# N32G401 register map
Vendor: Nationstech Ltd.; File version: 1.0
Registers are 32-bit, read-write, reset 0x0 unless marked. A register's access mark holds for its fields unless they carry their own. Offsets are from the block's base; [hi:lo] are bit positions; {n}, {i} and the like mark numbered series.

## TIM1 — Advanced timer
Base 0x40012C00
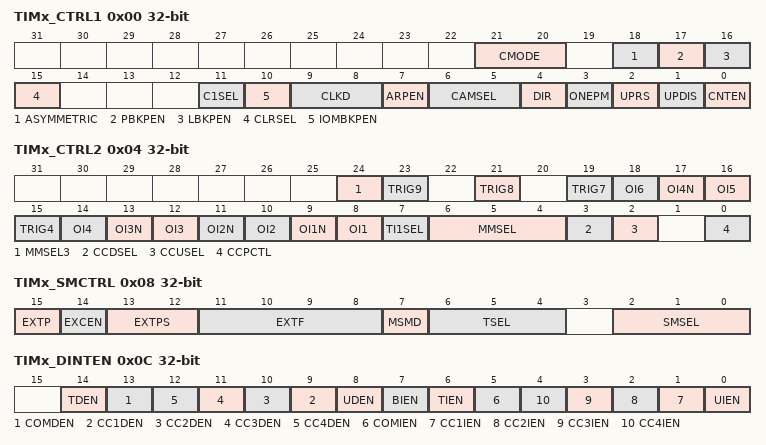
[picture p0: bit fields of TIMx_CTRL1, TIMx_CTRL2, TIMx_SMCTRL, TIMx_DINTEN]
0x00 TIMx_CTRL1 (reset mask 0x3FFFF)
  [21:20] CMODE, [18] ASYMMETRIC, [17] PBKPEN, [16] LBKPEN, [15] CLRSEL, [11] C1SEL, [10] IOMBKPEN, [9:8] CLKD, [7] ARPEN, [6:5] CAMSEL, [4] DIR, [3] ONEPM, [2] UPRS, [1] UPDIS, [0] CNTEN
0x04 TIMx_CTRL2 (reset mask 0x57FFD)
  [24] MMSEL3
  [23] TRIG9
  [21] TRIG8
  [19] TRIG7
  [2n+6] OI{n} (n=1..6)
  [17] OI4N — OI5
  [15] TRIG4
  [13] OI3N
  [11] OI2N
  [9] OI1N
  [7] TI1SEL
  [6:4] MMSEL
  [3] CCDSEL
  [2] CCUSEL
  [0] CCPCTL
0x08 TIMx_SMCTRL
  [15] EXTP, [14] EXCEN, [13:12] EXTPS, [11:8] EXTF, [7] MSMD, [6:4] TSEL, [2:0] SMSEL
0x0C TIMx_DINTEN
  [14] TDEN, [13] COMDEN, [n+8] CC{n}DEN (n=1..4), [8] UDEN, [7] BIEN, [6] TIEN, [5] COMIEN, [n] CC{n}IEN (n=1..4), [0] UIEN
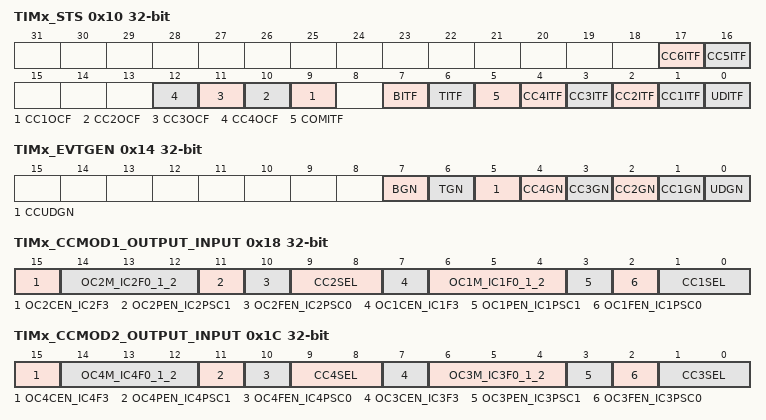
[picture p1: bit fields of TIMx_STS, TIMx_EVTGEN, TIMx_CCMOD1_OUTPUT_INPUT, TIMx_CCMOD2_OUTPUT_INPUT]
0x10 TIMx_STS
  [17] CC6ITF, [16] CC5ITF, [n+8] CC{n}OCF (n=1..4), [7] BITF, [6] TITF, [5] COMITF, [n] CC{n}ITF (n=1..4), [0] UDITF
0x14 TIMx_EVTGEN
  [7] BGN, [6] TGN, [5] CCUDGN, [n] CC{n}GN (n=1..4), [0] UDGN
0x18 TIMx_CCMOD1_OUTPUT_INPUT
  [15] OC2CEN_IC2F3, [14:12] OC2M_IC2F0_1_2, [11] OC2PEN_IC2PSC1, [10] OC2FEN_IC2PSC0, [9:8] CC2SEL, [7] OC1CEN_IC1F3, [6:4] OC1M_IC1F0_1_2, [3] OC1PEN_IC1PSC1, [2] OC1FEN_IC1PSC0, [1:0] CC1SEL
0x1C TIMx_CCMOD2_OUTPUT_INPUT
  [15] OC4CEN_IC4F3, [14:12] OC4M_IC4F0_1_2, [11] OC4PEN_IC4PSC1, [10] OC4FEN_IC4PSC0, [9:8] CC4SEL, [7] OC3CEN_IC3F3, [6:4] OC3M_IC3F0_1_2, [3] OC3PEN_IC3PSC1, [2] OC3FEN_IC3PSC0, [1:0] CC3SEL
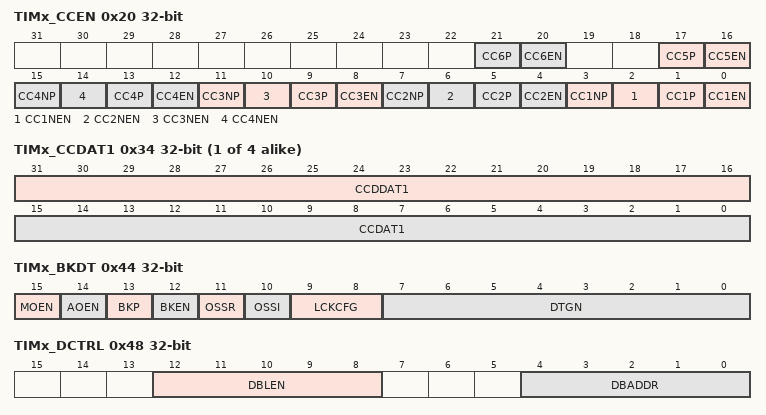
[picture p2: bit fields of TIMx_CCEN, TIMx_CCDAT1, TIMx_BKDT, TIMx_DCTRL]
0x20 TIMx_CCEN (reset mask 0x333FFF)
  [4n-3] CC{n}P (n=1..6), [4n-4] CC{n}EN (n=1..6), [4n-1] CC{n}NP (n=1..4), [4n-2] CC{n}NEN (n=1..4)
0x24 TIMx_CNT
  [15:0] CNT
0x28 TIMx_PSC
  [15:0] PSC
0x2C TIMx_AR
  [15:0] AR
0x30 TIMx_REPCNT
  [7:0] REPCNT
{0x30+4i} TIMx_CCDAT{i} (reset mask 0xFFFF) (i=1..4)
  [31:16] CCDDAT{i}, [15:0] CCDAT{i}
0x44 TIMx_BKDT
  [15] MOEN, [14] AOEN, [13] BKP, [12] BKEN, [11] OSSR, [10] OSSI, [9:8] LCKCFG, [7:0] DTGN
0x48 TIMx_DCTRL
  [12:8] DBLEN, [4:0] DBADDR
0x4C TIMx_DADDR
  [15:0] BURST
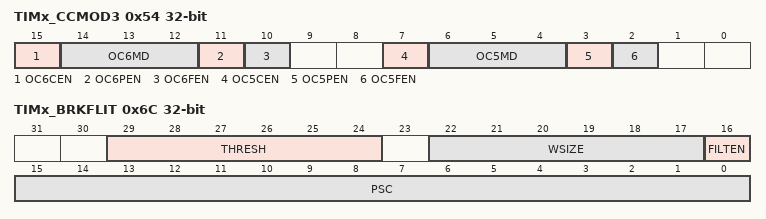
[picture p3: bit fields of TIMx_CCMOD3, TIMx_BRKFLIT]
0x54 TIMx_CCMOD3
  [15] OC6CEN, [14:12] OC6MD, [11] OC6PEN, [10] OC6FEN, [7] OC5CEN, [6:4] OC5MD, [3] OC5PEN, [2] OC5FEN
{0x44+4i} TIMx_CCDAT{i} (i=5..9)
  [15:0] CCDAT{i}
0x6C TIMx_BRKFLIT (reset mask 0xFFFF)
  [29:24] THRESH, [22:17] WSIZE, [16] FILTEN, [15:0] PSC

## TIM8 — Advanced timer
Base 0x40013400
Registers as TIM1, without TIMx_CCDAT{n} (n=7..9); these are added or differ:
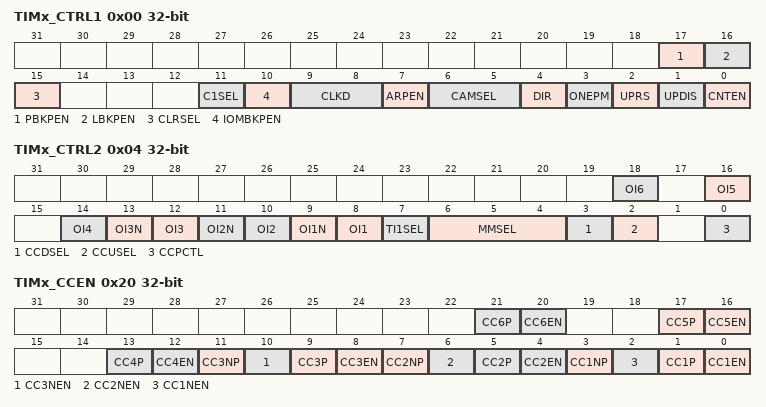
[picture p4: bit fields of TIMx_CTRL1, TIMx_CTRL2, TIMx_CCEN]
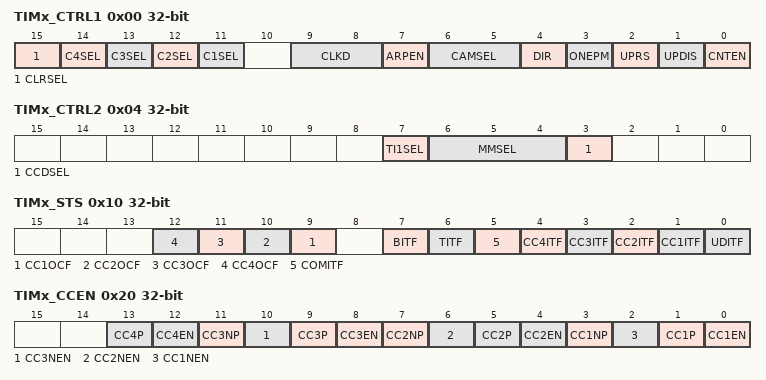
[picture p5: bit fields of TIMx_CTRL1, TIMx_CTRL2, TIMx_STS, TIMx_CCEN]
0x00 TIMx_CTRL1
  [17] PBKPEN, [16] LBKPEN, [15] CLRSEL, [11] C1SEL, [10] IOMBKPEN, [9:8] CLKD, [7] ARPEN, [6:5] CAMSEL, [4] DIR, [3] ONEPM, [2] UPRS, [1] UPDIS, [0] CNTEN
0x04 TIMx_CTRL2
  [2n+6] OI{n} (n=1..6), [13] OI3N, [11] OI2N, [9] OI1N, [7] TI1SEL, [6:4] MMSEL, [3] CCDSEL, [2] CCUSEL, [0] CCPCTL
0x20 TIMx_CCEN
  [4n-3] CC{n}P (n=1..6), [4n-4] CC{n}EN (n=1..6), [11] CC3NP, [10] CC3NEN, [7] CC2NP, [6] CC2NEN, [3] CC1NP, [2] CC1NEN
{0x30+4i} TIMx_CCDAT{i} (i=1..4)
  [15:0] CCDAT{i}

## TIM2 — General purpose timer
Base 0x40000000
Registers as TIM8, without TIMx_REPCNT, TIMx_BKDT, TIMx_CCMOD3, TIMx_CCDAT5, TIMx_CCDAT6, TIMx_BRKFLIT; these are added or differ:
0x00 TIMx_CTRL1
  [15] CLRSEL, [n+10] C{n}SEL (n=1..4), [9:8] CLKD, [7] ARPEN, [6:5] CAMSEL, [4] DIR, [3] ONEPM, [2] UPRS, [1] UPDIS, [0] CNTEN
0x04 TIMx_CTRL2
  [7] TI1SEL, [6:4] MMSEL, [3] CCDSEL
0x10 TIMx_STS
  [n+8] CC{n}OCF (n=1..4), [7] BITF, [6] TITF, [5] COMITF, [n] CC{n}ITF (n=1..4), [0] UDITF
0x20 TIMx_CCEN
  [4n-3] CC{n}P (n=1..4), [4n-4] CC{n}EN (n=1..4), [11] CC3NP, [10] CC3NEN, [7] CC2NP, [6] CC2NEN, [3] CC1NP, [2] CC1NEN
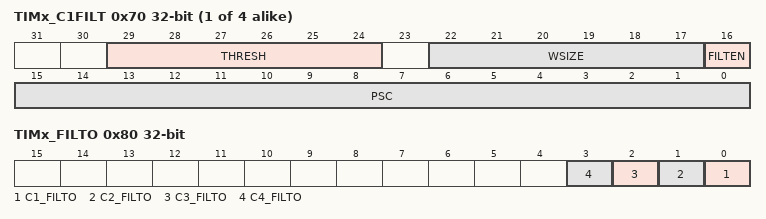
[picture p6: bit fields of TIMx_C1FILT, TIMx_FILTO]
{0x6C+4i} TIMx_C{i}FILT (reset mask 0xFFFF) (i=1..4)
  [29:24] THRESH, [22:17] WSIZE, [16] FILTEN, [15:0] PSC
0x80 TIMx_FILTO
  [n-1] C{n}_FILTO (n=1..4)

## TIM3 — General purpose timer
Base 0x40000400
Registers as TIM2; these are added or differ:
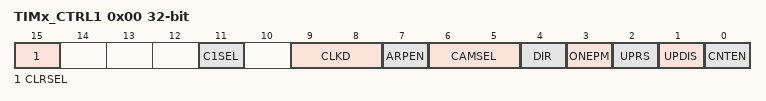
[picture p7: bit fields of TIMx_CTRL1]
0x00 TIMx_CTRL1
  [15] CLRSEL, [11] C1SEL, [9:8] CLKD, [7] ARPEN, [6:5] CAMSEL, [4] DIR, [3] ONEPM, [2] UPRS, [1] UPDIS, [0] CNTEN

## TIM4 — General purpose timer
Base 0x40000800
Registers as TIM3; these are added or differ:
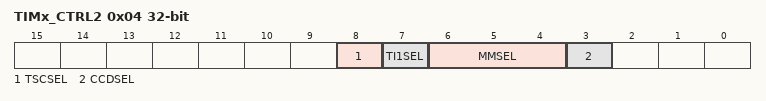
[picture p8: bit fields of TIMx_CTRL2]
0x04 TIMx_CTRL2
  [8] TSCSEL — TI1SEL
  [7] TI1SEL
  [6:4] MMSEL
  [3] CCDSEL

## TIM5 — General purpose timer
Base 0x40000C00
Registers as TIM2, without TIMx_CCMOD2_OUTPUT_INPUT; these are added or differ:
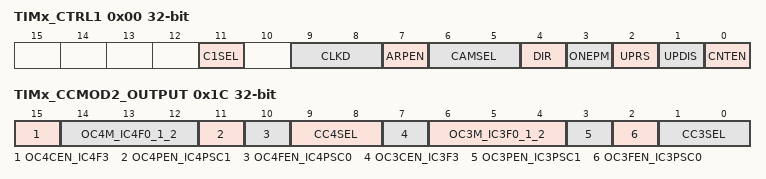
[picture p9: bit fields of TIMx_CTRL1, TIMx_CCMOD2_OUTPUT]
0x00 TIMx_CTRL1
  [11] C1SEL, [9:8] CLKD, [7] ARPEN, [6:5] CAMSEL, [4] DIR, [3] ONEPM, [2] UPRS, [1] UPDIS, [0] CNTEN
0x1C TIMx_CCMOD2_OUTPUT — TIMx_CCMOD2_OUTPUT_INPUT
  [15] OC4CEN_IC4F3, [14:12] OC4M_IC4F0_1_2, [11] OC4PEN_IC4PSC1, [10] OC4FEN_IC4PSC0, [9:8] CC4SEL, [7] OC3CEN_IC3F3, [6:4] OC3M_IC3F0_1_2, [3] OC3PEN_IC3PSC1, [2] OC3FEN_IC3PSC0, [1:0] CC3SEL
